# iostm32f205zx register map
Registers are 32-bit, access not given, no defined reset value unless marked. A register's access mark holds for its fields unless they carry their own. Addresses are absolute; registers are grouped by the start of their names; [hi:lo] are bit positions; {n}, {i} and the like mark numbered series.

## TIM14
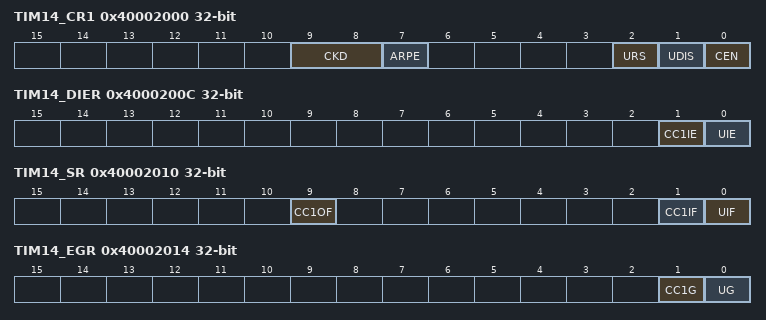
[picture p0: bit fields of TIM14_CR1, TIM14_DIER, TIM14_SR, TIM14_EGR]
0x40002000 TIM14_CR1
  [9:8] CKD, [7] ARPE, [2] URS, [1] UDIS, [0] CEN
0x4000200C TIM14_DIER
  [1] CC1IE, [0] UIE
0x40002010 TIM14_SR
  [9] CC1OF, [1] CC1IF, [0] UIF
0x40002014 TIM14_EGR
  [1] CC1G, [0] UG
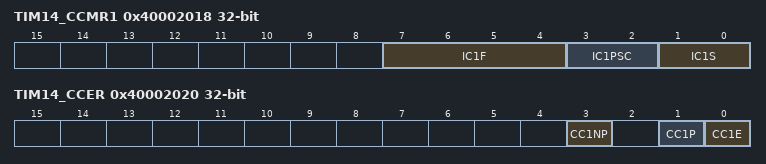
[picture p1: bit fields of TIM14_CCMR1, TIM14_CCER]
0x40002018 TIM14_CCMR1
  [7:4] IC1F, [3:2] IC1PSC, [1:0] IC1S
0x40002018 TIM14_OCMR1
0x40002020 TIM14_CCER
  [3] CC1NP, [1] CC1P, [0] CC1E
0x40002024 TIM14_CNT
  [15:0] CNT
0x40002028 TIM14_PSC
  [15:0] PSC
0x4000202C TIM14_ARR
  [15:0] ARR
0x40002034 TIM14_CCR1
  [15:0] CCR

## CAN1
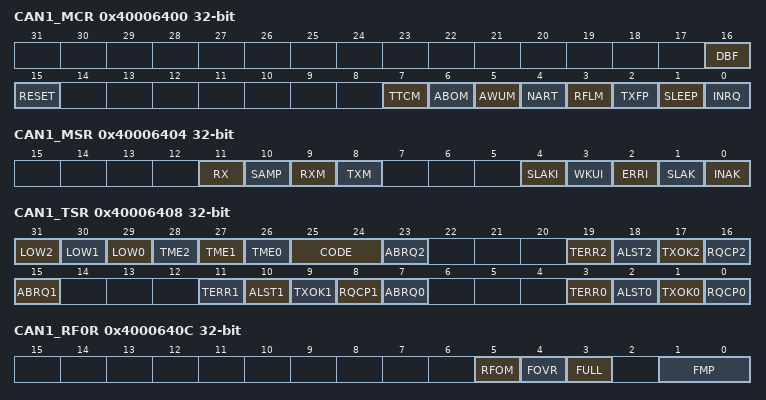
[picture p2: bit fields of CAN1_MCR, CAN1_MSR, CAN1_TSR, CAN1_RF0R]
0x40006400 CAN1_MCR
  [16] DBF, [15] RESET, [7] TTCM, [6] ABOM, [5] AWUM, [4] NART, [3] RFLM, [2] TXFP, [1] SLEEP, [0] INRQ
0x40006404 CAN1_MSR
  [11] RX, [10] SAMP, [9] RXM, [8] TXM, [4] SLAKI, [3] WKUI, [2] ERRI, [1] SLAK, [0] INAK
0x40006408 CAN1_TSR
  [31] LOW2, [30] LOW1, [29] LOW0, [28] TME2, [27] TME1, [26] TME0, [25:24] CODE, [23] ABRQ2, [19] TERR2, [18] ALST2, [17] TXOK2, [16] RQCP2, [15] ABRQ1, [11] TERR1, [10] ALST1, [9] TXOK1, [8] RQCP1, [7] ABRQ0, [3] TERR0, [2] ALST0, [1] TXOK0, [0] RQCP0
0x4000640C CAN1_RF0R
  [5] RFOM, [4] FOVR, [3] FULL, [1:0] FMP
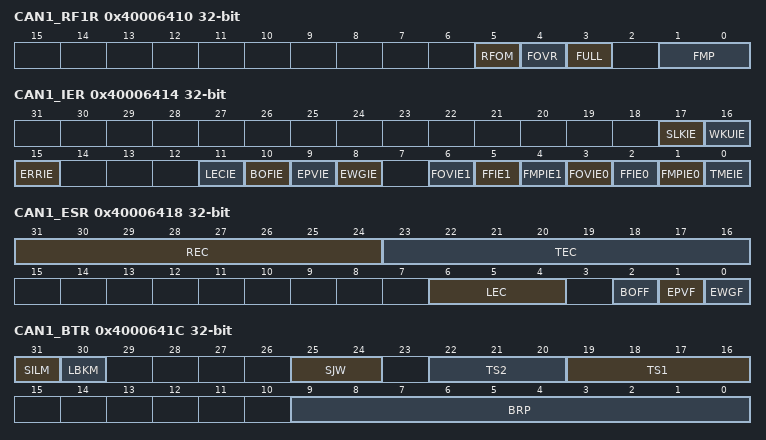
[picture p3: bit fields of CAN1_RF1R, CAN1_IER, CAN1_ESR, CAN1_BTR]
0x40006410 CAN1_RF1R
  [5] RFOM, [4] FOVR, [3] FULL, [1:0] FMP
0x40006414 CAN1_IER
  [17] SLKIE, [16] WKUIE, [15] ERRIE, [11] LECIE, [10] BOFIE, [9] EPVIE, [8] EWGIE, [6] FOVIE1, [5] FFIE1, [4] FMPIE1, [3] FOVIE0, [2] FFIE0, [1] FMPIE0, [0] TMEIE
0x40006418 CAN1_ESR
  [31:24] REC, [23:16] TEC, [6:4] LEC, [2] BOFF, [1] EPVF, [0] EWGF
0x4000641C CAN1_BTR
  [31] SILM, [30] LBKM, [25:24] SJW, [22:20] TS2, [19:16] TS1, [9:0] BRP
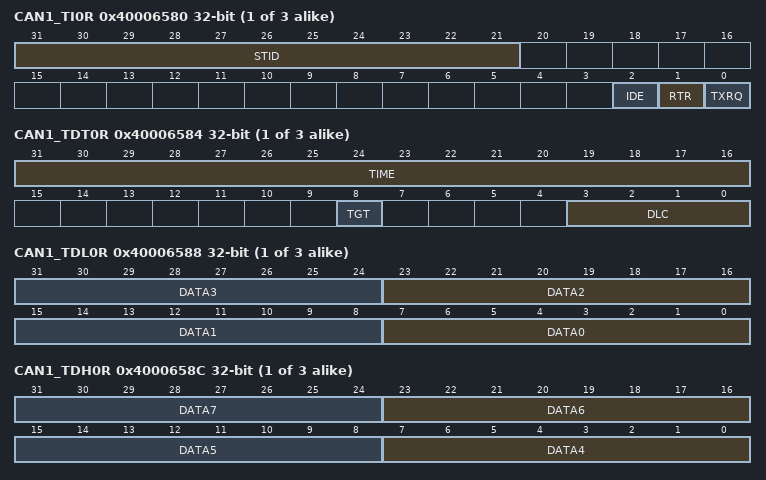
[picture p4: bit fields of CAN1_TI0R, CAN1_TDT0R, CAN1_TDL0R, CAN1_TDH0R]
{0x40006580+0x10*i} CAN1_TI{i}R (i=0..2)
  [31:21] STID, [2] IDE, [1] RTR, [0] TXRQ
{0x40006584+0x10*i} CAN1_TDT{i}R (i=0..2)
  [31:16] TIME, [8] TGT, [3:0] DLC
{0x40006588+0x10*i} CAN1_TDL{i}R (i=0..2)
  [8n+7:8n] DATA{n} (n=0..3)
{0x4000658C+0x10*i} CAN1_TDH{i}R (i=0..2)
  [8n-25:8n-32] DATA{n} (n=4..7)
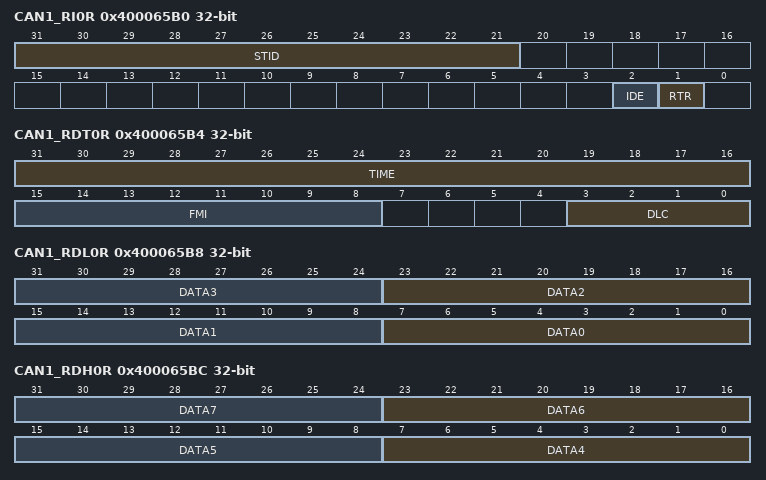
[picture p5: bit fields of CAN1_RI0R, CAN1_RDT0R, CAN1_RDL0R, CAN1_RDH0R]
0x400065B0 CAN1_RI0R
  [31:21] STID, [2] IDE, [1] RTR
0x400065B4 CAN1_RDT0R
  [31:16] TIME, [15:8] FMI, [3:0] DLC
0x400065B8 CAN1_RDL0R
  [8n+7:8n] DATA{n} (n=0..3)
0x400065BC CAN1_RDH0R
  [8n-25:8n-32] DATA{n} (n=4..7)
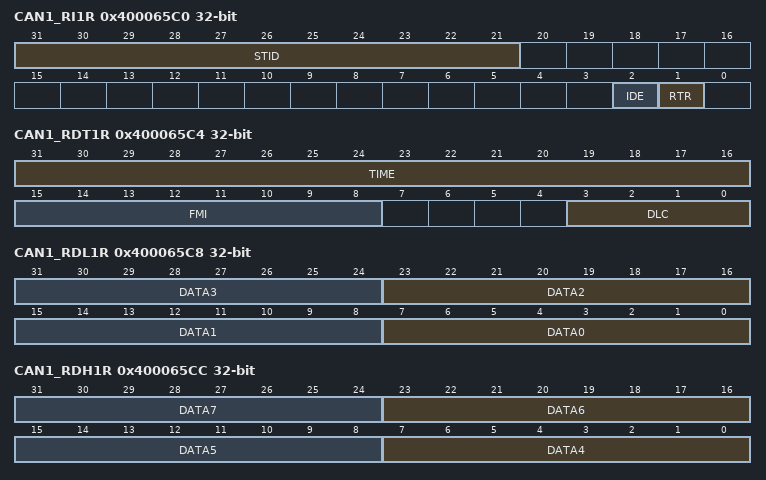
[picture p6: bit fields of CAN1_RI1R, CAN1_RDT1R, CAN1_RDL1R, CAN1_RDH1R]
0x400065C0 CAN1_RI1R
  [31:21] STID, [2] IDE, [1] RTR
0x400065C4 CAN1_RDT1R
  [31:16] TIME, [15:8] FMI, [3:0] DLC
0x400065C8 CAN1_RDL1R
  [8n+7:8n] DATA{n} (n=0..3)
0x400065CC CAN1_RDH1R
  [8n-25:8n-32] DATA{n} (n=4..7)

## CAN2
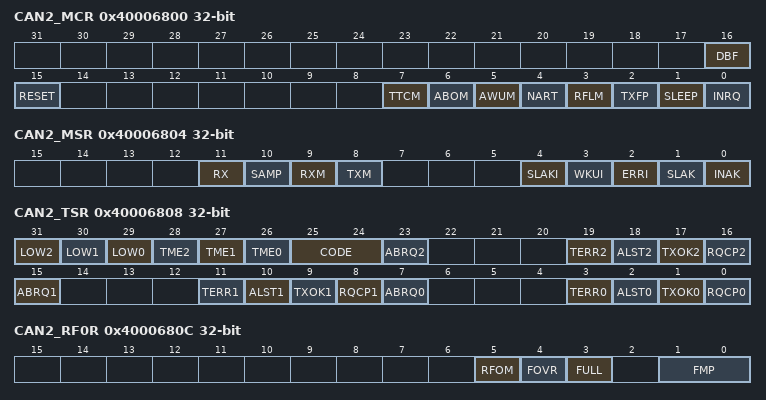
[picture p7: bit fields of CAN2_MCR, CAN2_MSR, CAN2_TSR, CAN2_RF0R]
0x40006800 CAN2_MCR
  [16] DBF, [15] RESET, [7] TTCM, [6] ABOM, [5] AWUM, [4] NART, [3] RFLM, [2] TXFP, [1] SLEEP, [0] INRQ
0x40006804 CAN2_MSR
  [11] RX, [10] SAMP, [9] RXM, [8] TXM, [4] SLAKI, [3] WKUI, [2] ERRI, [1] SLAK, [0] INAK
0x40006808 CAN2_TSR
  [31] LOW2, [30] LOW1, [29] LOW0, [28] TME2, [27] TME1, [26] TME0, [25:24] CODE, [23] ABRQ2, [19] TERR2, [18] ALST2, [17] TXOK2, [16] RQCP2, [15] ABRQ1, [11] TERR1, [10] ALST1, [9] TXOK1, [8] RQCP1, [7] ABRQ0, [3] TERR0, [2] ALST0, [1] TXOK0, [0] RQCP0
0x4000680C CAN2_RF0R
  [5] RFOM, [4] FOVR, [3] FULL, [1:0] FMP
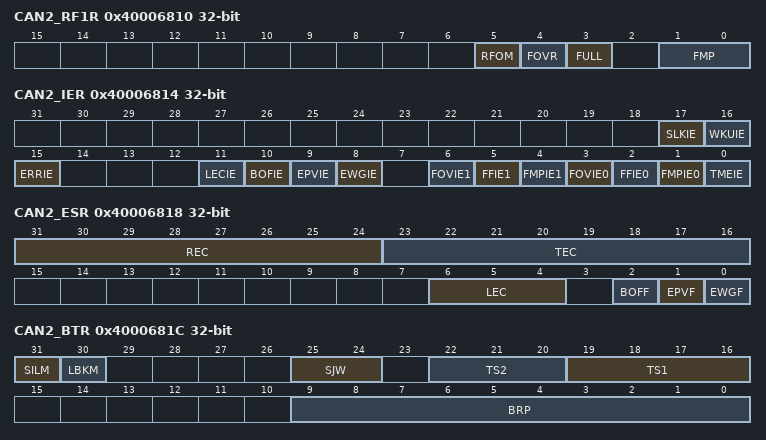
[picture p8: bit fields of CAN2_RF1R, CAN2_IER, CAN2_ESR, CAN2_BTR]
0x40006810 CAN2_RF1R
  [5] RFOM, [4] FOVR, [3] FULL, [1:0] FMP
0x40006814 CAN2_IER
  [17] SLKIE, [16] WKUIE, [15] ERRIE, [11] LECIE, [10] BOFIE, [9] EPVIE, [8] EWGIE, [6] FOVIE1, [5] FFIE1, [4] FMPIE1, [3] FOVIE0, [2] FFIE0, [1] FMPIE0, [0] TMEIE
0x40006818 CAN2_ESR
  [31:24] REC, [23:16] TEC, [6:4] LEC, [2] BOFF, [1] EPVF, [0] EWGF
0x4000681C CAN2_BTR
  [31] SILM, [30] LBKM, [25:24] SJW, [22:20] TS2, [19:16] TS1, [9:0] BRP
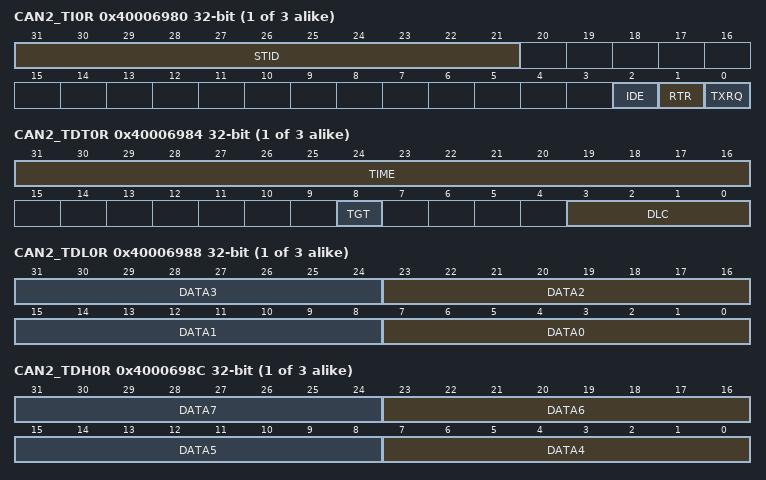
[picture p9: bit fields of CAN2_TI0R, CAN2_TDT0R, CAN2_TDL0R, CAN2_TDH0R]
{0x40006980+0x10*i} CAN2_TI{i}R (i=0..2)
  [31:21] STID, [2] IDE, [1] RTR, [0] TXRQ
{0x40006984+0x10*i} CAN2_TDT{i}R (i=0..2)
  [31:16] TIME, [8] TGT, [3:0] DLC
{0x40006988+0x10*i} CAN2_TDL{i}R (i=0..2)
  [8n+7:8n] DATA{n} (n=0..3)
{0x4000698C+0x10*i} CAN2_TDH{i}R (i=0..2)
  [8n-25:8n-32] DATA{n} (n=4..7)
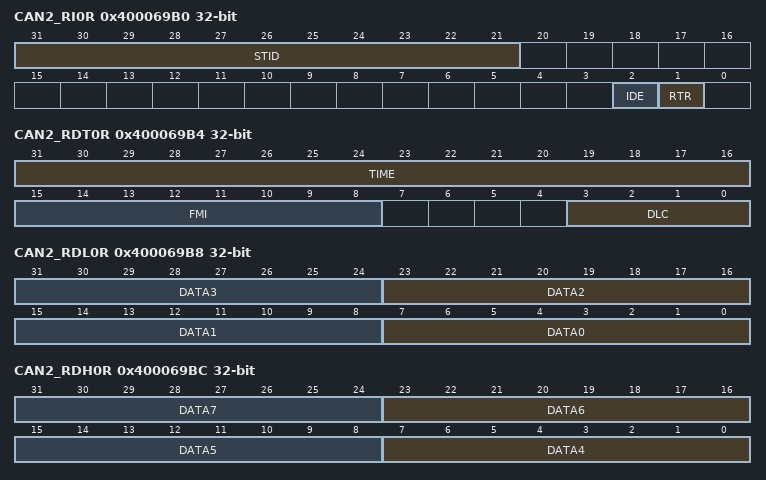
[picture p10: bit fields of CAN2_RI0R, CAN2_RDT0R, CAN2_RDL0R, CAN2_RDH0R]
0x400069B0 CAN2_RI0R
  [31:21] STID, [2] IDE, [1] RTR
0x400069B4 CAN2_RDT0R
  [31:16] TIME, [15:8] FMI, [3:0] DLC
0x400069B8 CAN2_RDL0R
  [8n+7:8n] DATA{n} (n=0..3)
0x400069BC CAN2_RDH0R
  [8n-25:8n-32] DATA{n} (n=4..7)
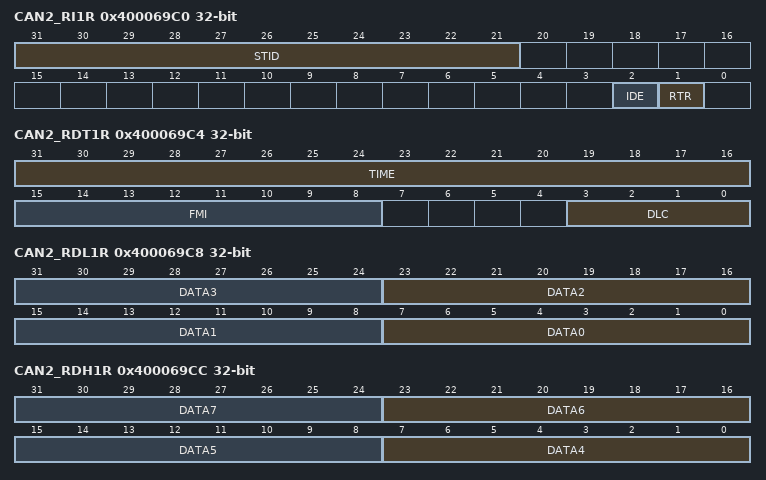
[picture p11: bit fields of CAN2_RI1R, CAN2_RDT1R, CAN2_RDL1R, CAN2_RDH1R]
0x400069C0 CAN2_RI1R
  [31:21] STID, [2] IDE, [1] RTR
0x400069C4 CAN2_RDT1R
  [31:16] TIME, [15:8] FMI, [3:0] DLC
0x400069C8 CAN2_RDL1R
  [8n+7:8n] DATA{n} (n=0..3)
0x400069CC CAN2_RDH1R
  [8n-25:8n-32] DATA{n} (n=4..7)
